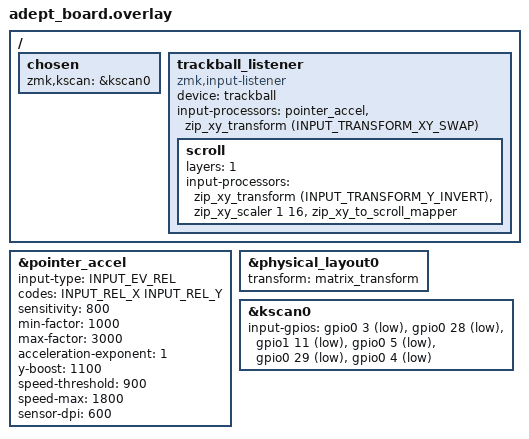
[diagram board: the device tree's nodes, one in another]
#include "adept.dtsi"
#include "pmw3610.dtsi"
#include "adept-layouts.dtsi"
#include <input/processors.dtsi>
#include <dt-bindings/zmk/input_transform.h>
#include <behaviors/input_gestures_accel.dtsi>

&pointer_accel { // this needs to be put BEFORE input-listener
    input-type = <INPUT_EV_REL>;
    codes = <INPUT_REL_X INPUT_REL_Y>;
    sensitivity = <800>;         // 0.8x base sensitivity
	min-factor = <800>;			  // 0.8x minimum for percision
    max-factor = <3000>;          // 3.0x maximum acceleration
    acceleration-exponent = <1>;  // Advanced exponential curve (1-5)
    y-boost = <1100>;             // 1.1x Y-axis boost for widescreen
    speed-threshold = <900>;      // Start acceleration at 900 counts/sec, just 1.5 inch/sec
    speed-max = <1800>;           // Max acceleration at 1800 counts/sec, just 3 inch/sec
    min-factor = <1000>;          // 1.0x minimum (no deceleration)
	sensor-dpi = <600>;
};

/* More about input processors: https://zmk.dev/docs/keymaps/input-processors#input-processors-overview */

&physical_layout0 {
    transform = <&matrix_transform>;
};

&kscan0 {
    input-gpios
    = <&gpio0  3 (GPIO_ACTIVE_LOW | GPIO_PULL_UP)> // sw_1
    , <&gpio0 28 (GPIO_ACTIVE_LOW | GPIO_PULL_UP)> // sw_2
    , <&gpio1 11 (GPIO_ACTIVE_LOW | GPIO_PULL_UP)> // sw_6
    , <&gpio0  5 (GPIO_ACTIVE_LOW | GPIO_PULL_UP)> // sw_5
    , <&gpio0 29 (GPIO_ACTIVE_LOW | GPIO_PULL_UP)> // sw_3
    , <&gpio0  4 (GPIO_ACTIVE_LOW | GPIO_PULL_UP)> // sw_4
    ;
};

/ {
    chosen {
        zmk,kscan = &kscan0;
    };

    trackball_listener { // listener for input device
        compatible = "zmk,input-listener";
        device = <&trackball>;
        input-processors =
            <&pointer_accel>,
            <&zip_xy_transform (INPUT_TRANSFORM_XY_SWAP)>;

        scroll {
            layers = <1>; // scroll_layer
            input-processors =
            <&zip_xy_transform (INPUT_TRANSFORM_Y_INVERT)>,
            <&zip_xy_scaler 1 16>,
            <&zip_xy_to_scroll_mapper>;
        };
    };
};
